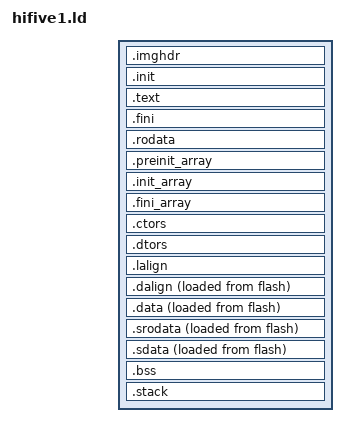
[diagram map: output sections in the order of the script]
/*
 * Licensed to the Apache Software Foundation (ASF) under one
 * or more contributor license agreements.  See the NOTICE file
 * distributed with this work for additional information
 * regarding copyright ownership.  The ASF licenses this file
 * to you under the Apache License, Version 2.0 (the
 * "License"); you may not use this file except in compliance
 * with the License.  You may obtain a copy of the License at
 *
 *  http://www.apache.org/licenses/LICENSE-2.0
 *
 * Unless required by applicable law or agreed to in writing,
 * software distributed under the License is distributed on an
 * "AS IS" BASIS, WITHOUT WARRANTIES OR CONDITIONS OF ANY
 * KIND, either express or implied.  See the License for the
 * specific language governing permissions and limitations
 * under the License.
 */

OUTPUT_ARCH( "riscv" )

ENTRY( _reset_handler )

SECTIONS
{
  __stack_size = DEFINED(__stack_size) ? __stack_size : 2K;
  .imghdr (NOLOAD):
  {
      . = . + _imghdr_size;
  } >flash

  .init           :
  {
    KEEP (*(SORT_NONE(.init)))
  } >flash

  .text           :
  {
    *(.text.unlikely .text.unlikely.*)
    *(.text.startup .text.startup.*)
    *(.text .text.*)
    *(.gnu.linkonce.t.*)
  } >flash

  .fini           :
  {
    KEEP (*(SORT_NONE(.fini)))
  } >flash

  PROVIDE (__etext = .);
  PROVIDE (_etext = .);
  PROVIDE (etext = .);

  .rodata         :
  {
    *(.rdata)
    *(.rodata .rodata.*)
    *(.gnu.linkonce.r.*)
  } >flash

  . = ALIGN(4);

  .preinit_array  :
  {
    PROVIDE_HIDDEN (__preinit_array_start = .);
    KEEP (*(.preinit_array))
    PROVIDE_HIDDEN (__preinit_array_end = .);
  } >flash

  .init_array     :
  {
    PROVIDE_HIDDEN (__init_array_start = .);
    KEEP (*(SORT_BY_INIT_PRIORITY(.init_array.*) SORT_BY_INIT_PRIORITY(.ctors.*)))
    KEEP (*(.init_array EXCLUDE_FILE (*crtbegin.o *crtbegin?.o *crtend.o *crtend?.o ) .ctors))
    PROVIDE_HIDDEN (__init_array_end = .);
  } >flash

  .fini_array     :
  {
    PROVIDE_HIDDEN (__fini_array_start = .);
    KEEP (*(SORT_BY_INIT_PRIORITY(.fini_array.*) SORT_BY_INIT_PRIORITY(.dtors.*)))
    KEEP (*(.fini_array EXCLUDE_FILE (*crtbegin.o *crtbegin?.o *crtend.o *crtend?.o ) .dtors))
    PROVIDE_HIDDEN (__fini_array_end = .);
  } >flash

  .ctors          :
  {
    /* gcc uses crtbegin.o to find the start of
       the constructors, so we make sure it is
       first.  Because this is a wildcard, it
       doesn't matter if the user does not
       actually link against crtbegin.o; the
       linker won't look for a file to match a
       wildcard.  The wildcard also means that it
       doesn't matter which directory crtbegin.o
       is in.  */
    KEEP (*crtbegin.o(.ctors))
    KEEP (*crtbegin?.o(.ctors))
    /* We don't want to include the .ctor section from
       the crtend.o file until after the sorted ctors.
       The .ctor section from the crtend file contains the
       end of ctors marker and it must be last */
    KEEP (*(EXCLUDE_FILE (*crtend.o *crtend?.o ) .ctors))
    KEEP (*(SORT(.ctors.*)))
    KEEP (*(.ctors))
  } >flash

  .dtors          :
  {
    KEEP (*crtbegin.o(.dtors))
    KEEP (*crtbegin?.o(.dtors))
    KEEP (*(EXCLUDE_FILE (*crtend.o *crtend?.o ) .dtors))
    KEEP (*(SORT(.dtors.*)))
    KEEP (*(.dtors))
  } >flash

  .lalign         :
  {
    . = ALIGN(4);
    PROVIDE( _data_lma = . );
  } >flash

  .dalign         :
  {
    . = ALIGN(4);
    PROVIDE( _data = . );
  } >ram AT>flash

  .data          :
  {
    *(.data .data.*)
    *(.gnu.linkonce.d.*)
  } >ram AT>flash

  .srodata        :
  {
    PROVIDE( _gp = . + 0x800 );
    PROVIDE( __global_pointer$ = _gp);
    *(.srodata.cst16)
    *(.srodata.cst8)
    *(.srodata.cst4)
    *(.srodata.cst2)
    *(.srodata .srodata.*)
  } >ram AT>flash

  .sdata          :
  {
    *(.sdata .sdata.*)
    *(.gnu.linkonce.s.*)
  } >ram AT>flash

  . = ALIGN(4);
  PROVIDE( _edata = . );
  PROVIDE( edata = . );

  PROVIDE( _fbss = . );
  PROVIDE( __bss_start = . );
  .bss            :
  {
    *(.sbss*)
    *(.gnu.linkonce.sb.*)
    *(.bss .bss.*)
    *(.gnu.linkonce.b.*)
    *(COMMON)
    . = ALIGN(4);
  } >ram

  . = ALIGN(8);
  PROVIDE( _end = . );
  PROVIDE( end = . );

  .stack ORIGIN(ram) + LENGTH(ram) - __stack_size :
  {
    PROVIDE( _heap_end = . );
    . = __stack_size;
    PROVIDE( _sp = . );
  } >ram

  _ram_start = ORIGIN(ram);
}
